AUTOSAR XML (schema 4-3-1)
package /Components
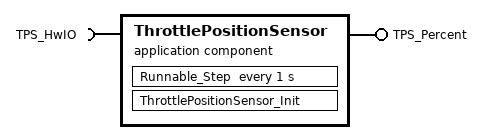
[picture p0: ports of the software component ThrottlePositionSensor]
  application sw component type ThrottlePositionSensor
    provide port TPS_Percent: nonqueued-sender-com-spec{data-element=Value_6, init-value=0}, provided-interface=TPS_Percent
    require port TPS_HwIO: nonqueued-receiver-com-spec{data-element=Value_5, init-value=0}, required-interface=TPS_HwIO
    behavior test_IB: handle-termination-and-restart=NO-SUPPORT
      timing event Event_Runnable_Step: start-on-event=Runnable_Step, period=1
      runnable Runnable_Step
        data-read-access:
          access IN_TPS_HwIO_Value_5: accessed-variable=TPS_HwIO.Value_5
        data-write-access:
          access OUT_TPS_Percent_Value_6: accessed-variable=TPS_Percent.Value_6
      runnable ThrottlePositionSensor_Init
      per-instance-parameters:
        parameter data prototype TPSPercent_LkupTbl: category=CURVE, sw-calibration-access=READ-WRITE, type=Appl_TPSPercent_LkupTbl, init-value=constant-reference={short-label=TPSPercent_LkupTbl, constant=TPSPercent_LkupTbl}
